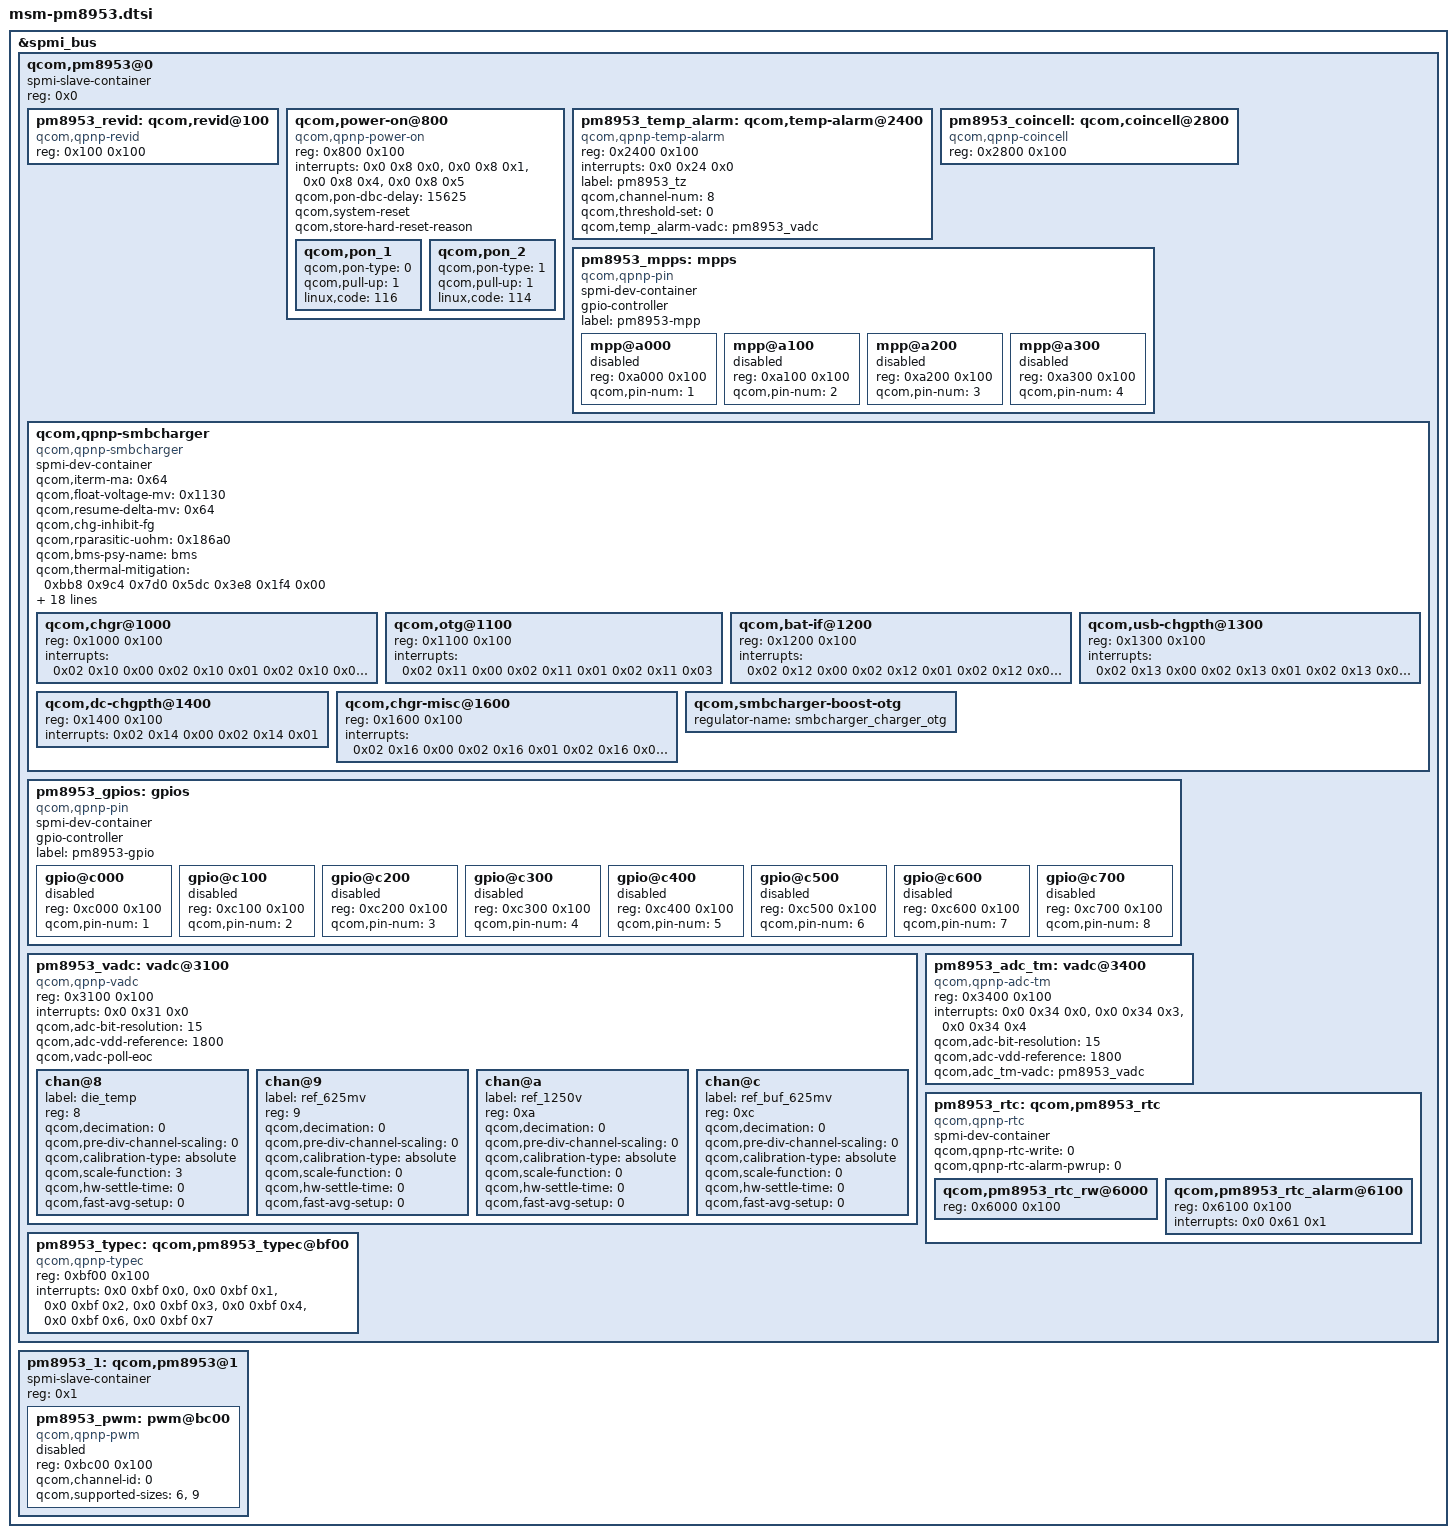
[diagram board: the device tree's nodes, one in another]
/*
 * Copyright (c) 2015-2016, 2018, The Linux Foundation. All rights reserved.
 *
 * This program is free software; you can redistribute it and/or modify
 * it under the terms of the GNU General Public License version 2 and
 * only version 2 as published by the Free Software Foundation.
 *
 * This program is distributed in the hope that it will be useful,
 * but WITHOUT ANY WARRANTY; without even the implied warranty of
 * MERCHANTABILITY or FITNESS FOR A PARTICULAR PURPOSE.  See the
 * GNU General Public License for more details.
 */

&spmi_bus {

	qcom,pm8953@0 {
		spmi-slave-container;
		reg = <0x0>;
		#address-cells = <1>;
		#size-cells = <1>;

		pm8953_revid: qcom,revid@100 {
			compatible = "qcom,qpnp-revid";
			reg = <0x100 0x100>;
		};

		qcom,power-on@800 {
			compatible = "qcom,qpnp-power-on";
			reg = <0x800 0x100>;
			interrupts = <0x0 0x8 0x0>,
				<0x0 0x8 0x1>,
				<0x0 0x8 0x4>,
				<0x0 0x8 0x5>;
			interrupt-names = "kpdpwr", "resin",
				"resin-bark", "kpdpwr-resin-bark";
			qcom,pon-dbc-delay = <15625>;
			qcom,system-reset;
			qcom,store-hard-reset-reason;

			qcom,pon_1 {
				qcom,pon-type = <0>;
				qcom,pull-up = <1>;
				linux,code = <116>;
			};

			qcom,pon_2 {
				qcom,pon-type = <1>;
				qcom,pull-up = <1>;
				linux,code = <114>;
			};
		};

		pm8953_temp_alarm: qcom,temp-alarm@2400 {
			compatible = "qcom,qpnp-temp-alarm";
			reg = <0x2400 0x100>;
			interrupts = <0x0 0x24 0x0>;
			label = "pm8953_tz";
			qcom,channel-num = <8>;
			qcom,threshold-set = <0>;
			qcom,temp_alarm-vadc = <&pm8953_vadc>;
		};

		pm8953_coincell: qcom,coincell@2800 {
			compatible = "qcom,qpnp-coincell";
			reg = <0x2800 0x100>;
		};

		pm8953_mpps: mpps {
			compatible = "qcom,qpnp-pin";
			spmi-dev-container;
			gpio-controller;
			#gpio-cells = <2>;
			#address-cells = <1>;
			#size-cells = <1>;
			label = "pm8953-mpp";

			mpp@a000 {
				reg = <0xa000 0x100>;
				qcom,pin-num = <1>;
				status = "disabled";
			};

			mpp@a100 {
				reg = <0xa100 0x100>;
				qcom,pin-num = <2>;
                status = "disabled";
			};

			mpp@a200 {
				reg = <0xa200 0x100>;
				qcom,pin-num = <3>;
				status = "disabled";
			};

			mpp@a300 {
				reg = <0xa300 0x100>;
				qcom,pin-num = <4>;
                status = "disabled";
			};
        };
            qcom,qpnp-smbcharger {
					spmi-dev-container;
					compatible = "qcom,qpnp-smbcharger";
					#address-cells = <0x01>;
					#size-cells = <0x01>;
					qcom,iterm-ma = <0x64>;
					qcom,float-voltage-mv = <0x1130>;
					qcom,resume-delta-mv = <0x64>;
					qcom,chg-inhibit-fg;
					qcom,rparasitic-uohm = <0x186a0>;
					qcom,bms-psy-name = "bms";
					qcom,thermal-mitigation = <0xbb8 0x9c4 0x7d0 0x5dc 0x3e8 0x1f4 0x00>;
					qcom,parallel-usb-min-current-ma = <0x578>;
					qcom,parallel-usb-9v-min-current-ma = <0x384>;
					qcom,parallel-allowed-lowering-ma = <0x1f4>;
					qcom,pmic-revid = <0x125>;
					qcom,force-aicl-rerun;
					qcom,aicl-rerun-period-s = <0xb4>;
					qcom,vchg_sns-vadc = <0x126>;
					qcom,vchg-adc-channel-id = <0x03>;
					qcom,vusbin-adc-channel-id = <0x00>;
					qcom,override-usb-current = <0x01>;
					qcom,usbchg_temp-vadc = <0x121>;
					qcom,board_temp-vadc = <0x121>;
					qcom,usbchg_temp-channel-id = <0x11>;
					qcom,board_temp-channel-id = <0x13>;
					qcom,parallel-en-gpio = <0x127 0x02 0x00>;
					qcom,charging-timeout-mins = <0x300>;
					qcom,precharging-timeout-mins = <0x30>;
					qcom,battery-data = <0x128>;
					status = "okay";

					qcom,chgr@1000 {
						reg = <0x1000 0x100>;
						interrupts = <0x02 0x10 0x00 0x02 0x10 0x01 0x02 0x10 0x02 0x02 0x10 0x03 0x02 0x10 0x04 0x02 0x10 0x05 0x02 0x10 0x06 0x02 0x10 0x07>;
						interrupt-names = "chg-error", "chg-inhibit", "chg-prechg-sft", "chg-complete-chg-sft", "chg-p2f-thr", "chg-rechg-thr", "chg-taper-thr", "chg-tcc-thr";
					};

					qcom,otg@1100 {
						reg = <0x1100 0x100>;
						interrupts = <0x02 0x11 0x00 0x02 0x11 0x01 0x02 0x11 0x03>;
						interrupt-names = "otg-fail", "otg-oc", "usbid-change";
					};

					qcom,bat-if@1200 {
						reg = <0x1200 0x100>;
						interrupts = <0x02 0x12 0x00 0x02 0x12 0x01 0x02 0x12 0x02 0x02 0x12 0x03 0x02 0x12 0x04 0x02 0x12 0x05 0x02 0x12 0x06 0x02 0x12 0x07>;
						interrupt-names = "batt-hot", "batt-warm", "batt-cold", "batt-cool", "batt-ov", "batt-low", "batt-missing", "batt-term-missing";
					};

					qcom,usb-chgpth@1300 {
						reg = <0x1300 0x100>;
						interrupts = <0x02 0x13 0x00 0x02 0x13 0x01 0x02 0x13 0x02 0x02 0x13 0x05>;
						interrupt-names = "usbin-uv", "usbin-ov", "usbin-src-det", "aicl-done";
					};

					qcom,dc-chgpth@1400 {
						reg = <0x1400 0x100>;
						interrupts = <0x02 0x14 0x00 0x02 0x14 0x01>;
						interrupt-names = "dcin-uv", "dcin-ov";
					};

					qcom,chgr-misc@1600 {
						reg = <0x1600 0x100>;
						interrupts = <0x02 0x16 0x00 0x02 0x16 0x01 0x02 0x16 0x02 0x02 0x16 0x03 0x02 0x16 0x04 0x02 0x16 0x05>;
						interrupt-names = "power-ok", "temp-shutdown", "wdog-timeout", "flash-fail", "otst2", "otst3";
					};

					qcom,smbcharger-boost-otg {
						regulator-name = "smbcharger_charger_otg";
						linux,phandle = <0x136>;
						phandle = <0x136>;
					};
				};

		pm8953_gpios: gpios {
			spmi-dev-container;
			compatible = "qcom,qpnp-pin";
			gpio-controller;
			#gpio-cells = <2>;
			#address-cells = <1>;
			#size-cells = <1>;
			label = "pm8953-gpio";

			gpio@c000 {
				reg = <0xc000 0x100>;
				qcom,pin-num = <1>;
				status = "disabled";
			};

			gpio@c100 {
				reg = <0xc100 0x100>;
				qcom,pin-num = <2>;
				status = "disabled";
			};

			gpio@c200 {
				reg = <0xc200 0x100>;
				qcom,pin-num = <3>;
				status = "disabled";
			};

			gpio@c300 {
				reg = <0xc300 0x100>;
				qcom,pin-num = <4>;
				status = "disabled";
			};

			gpio@c400 {
				reg = <0xc400 0x100>;
				qcom,pin-num = <5>;
				status = "disabled";
			};

			gpio@c500 {
				reg = <0xc500 0x100>;
				qcom,pin-num = <6>;
				status = "disabled";
			};

			gpio@c600 {
				reg = <0xc600 0x100>;
				qcom,pin-num = <7>;
				status = "disabled";
			};

			gpio@c700 {
				reg = <0xc700 0x100>;
				qcom,pin-num = <8>;
				status = "disabled";
			};
		};

		pm8953_vadc: vadc@3100 {
			compatible = "qcom,qpnp-vadc";
			reg = <0x3100 0x100>;
			#address-cells = <1>;
			#size-cells = <0>;
			interrupts = <0x0 0x31 0x0>;
			interrupt-names = "eoc-int-en-set";
			qcom,adc-bit-resolution = <15>;
			qcom,adc-vdd-reference = <1800>;
			qcom,vadc-poll-eoc;

			chan@8 {
				label = "die_temp";
				reg = <8>;
				qcom,decimation = <0>;
				qcom,pre-div-channel-scaling = <0>;
				qcom,calibration-type = "absolute";
				qcom,scale-function = <3>;
				qcom,hw-settle-time = <0>;
				qcom,fast-avg-setup = <0>;
			};

			chan@9 {
				label = "ref_625mv";
				reg = <9>;
				qcom,decimation = <0>;
				qcom,pre-div-channel-scaling = <0>;
				qcom,calibration-type = "absolute";
				qcom,scale-function = <0>;
				qcom,hw-settle-time = <0>;
				qcom,fast-avg-setup = <0>;
			};

			chan@a {
				label = "ref_1250v";
				reg = <0xa>;
				qcom,decimation = <0>;
				qcom,pre-div-channel-scaling = <0>;
				qcom,calibration-type = "absolute";
				qcom,scale-function = <0>;
				qcom,hw-settle-time = <0>;
				qcom,fast-avg-setup = <0>;
			};

			chan@c {
				label = "ref_buf_625mv";
				reg = <0xc>;
				qcom,decimation = <0>;
				qcom,pre-div-channel-scaling = <0>;
				qcom,calibration-type = "absolute";
				qcom,scale-function = <0>;
				qcom,hw-settle-time = <0>;
				qcom,fast-avg-setup = <0>;
			};
		};

		pm8953_adc_tm: vadc@3400 {
			compatible = "qcom,qpnp-adc-tm";
			reg = <0x3400 0x100>;
			#address-cells = <1>;
			#size-cells = <0>;
			interrupts =	<0x0 0x34 0x0>,
					<0x0 0x34 0x3>,
					<0x0 0x34 0x4>;
			interrupt-names =	"eoc-int-en-set",
						"high-thr-en-set",
						"low-thr-en-set";
			qcom,adc-bit-resolution = <15>;
			qcom,adc-vdd-reference = <1800>;
			qcom,adc_tm-vadc = <&pm8953_vadc>;

		};

		pm8953_rtc: qcom,pm8953_rtc {
			spmi-dev-container;
			compatible = "qcom,qpnp-rtc";
			#address-cells = <1>;
			#size-cells = <1>;
			qcom,qpnp-rtc-write = <0>;
			qcom,qpnp-rtc-alarm-pwrup = <0>;

			qcom,pm8953_rtc_rw@6000 {
				reg = <0x6000 0x100>;
			};

			qcom,pm8953_rtc_alarm@6100 {
				reg = <0x6100 0x100>;
				interrupts = <0x0 0x61 0x1>;
			};
		};

		pm8953_typec: qcom,pm8953_typec@bf00 {
			compatible = "qcom,qpnp-typec";
			reg = <0xbf00 0x100>;
			interrupts =    <0x0 0xbf 0x0>,
					<0x0 0xbf 0x1>,
					<0x0 0xbf 0x2>,
					<0x0 0xbf 0x3>,
					<0x0 0xbf 0x4>,
					<0x0 0xbf 0x6>,
					<0x0 0xbf 0x7>;

			interrupt-names =       "vrd-change",
						"ufp-detect",
						"ufp-detach",
						"dfp-detect",
						"dfp-detach",
						"vbus-err",
						"vconn-oc";
		};
	};

	pm8953_1: qcom,pm8953@1 {
		spmi-slave-container;
		reg = <0x1>;
		#address-cells = <1>;
		#size-cells = <1>;

		pm8953_pwm: pwm@bc00 {
			status = "disabled";
			compatible = "qcom,qpnp-pwm";
			reg = <0xbc00 0x100>;
			reg-names = "qpnp-lpg-channel-base";
			qcom,channel-id = <0>;
			qcom,supported-sizes = <6>, <9>;
			#pwm-cells = <2>;
		};
	};
};
